# S6E1A1 register map
File version: 1.1
Registers are 8-bit, read-write, reset 0x0 unless marked. A register's access mark holds for its fields unless they carry their own. Offsets are from the block's base; [hi:lo] are bit positions; {n}, {i} and the like mark numbered series.

## ADC0 — ADC0 Registers
Base 0x40027000
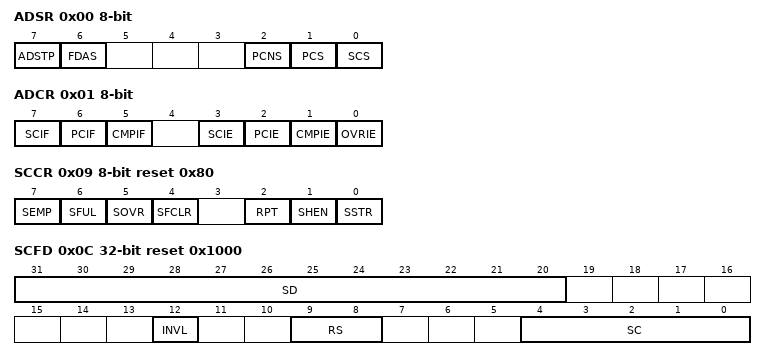
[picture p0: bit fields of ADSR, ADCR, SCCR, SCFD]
0x00 ADSR — A/D Status Register
  [7] ADSTP — A/D conversion forced stop bit
  [6] FDAS — FIFO data placement selection bit
  [2] PCNS ro — Priority conversion pending flag
  [1] PCS ro — Priority conversion status flag
  [0] SCS ro — Scan conversion status flag
0x01 ADCR — A/D Control Register
  [7] SCIF — Scan conversion interrupt request bit
  [6] PCIF — Priority conversion interrupt request bit
  [5] CMPIF — Conversion result comparison interrupt request bit
  [3] SCIE — Scan conversion interrupt enable bit
  [2] PCIE — Priority conversion interrupt enable bit
  [1] CMPIE — Conversion result comparison interrupt enable bit
  [0] OVRIE — FIFO overrun interrupt enable bit
0x08 SFNS — Scan Conversion FIFO Stage Count Setup Register
  [3:0] SFS — Scan conversion FIFO stage count setting bits
0x09 SCCR reset 0x80 — Scan Conversion Control Register
  [7] SEMP ro — Scan conversion FIFO empty bit
  [6] SFUL ro — Scan conversion FIFO full bit
  [5] SOVR — Scan conversion overrun flag
  [4] SFCLR — Scan conversion FIFO clear bit
  [2] RPT — Scan conversion repeat bit
  [1] SHEN — Scan conversion timer start enable bit
  [0] SSTR — Scan conversion start bit
0x0C SCFD 32-bit ro reset 0x1000 — Scan Conversion FIFO Data Register
  [31:20] SD — Scan conversion result
  [12] INVL — A/D conversion result disable bit
  [9:8] RS — Scan conversion start factor
  [4:0] SC — Conversion input channel bits
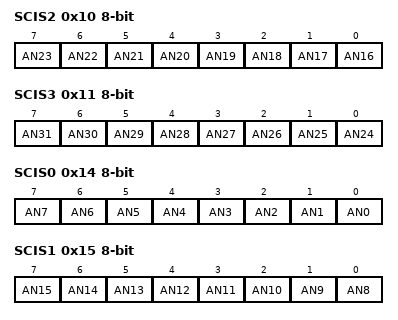
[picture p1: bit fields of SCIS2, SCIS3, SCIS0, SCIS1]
0x10 SCIS2 — Scan Conversion Input Selection Register 2
  [n-16] AN{n} (n=16..23) — AN{n} analog input selection bit
0x11 SCIS3 — Scan Conversion Input Selection Register 3
  [n-24] AN{n} (n=24..31) — AN{n} analog input selection bit
0x14 SCIS0 — Scan Conversion Input Selection Register 0
  [n] AN{n} (n=0..7) — AN{n} analog input selection bit
0x15 SCIS1 — Scan Conversion Input Selection Register 1
  [n-8] AN{n} (n=8..15) — AN{n} analog input selection bit
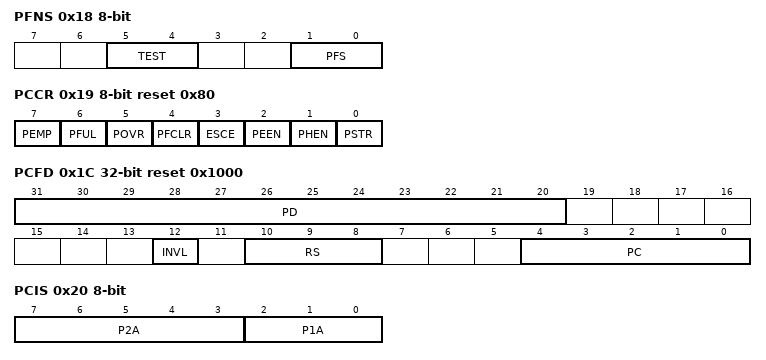
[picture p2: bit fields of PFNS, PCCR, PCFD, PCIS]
0x18 PFNS — Priority Conversion FIFO Stage Count Setup Register
  [5:4] TEST ro — Test bits
  [1:0] PFS — Priority conversion FIFO stage count setting bits
0x19 PCCR reset 0x80 — Priority Conversion Control Register
  [7] PEMP ro — Priority conversion FIFO empty bit
  [6] PFUL ro — Priority conversion FIFO full bit
  [5] POVR — Priority conversion overrun flag
  [4] PFCLR — Priority conversion FIFO clear bit
  [3] ESCE — External trigger analog input selection bit
  [2] PEEN — Priority conversion external start enable bit
  [1] PHEN — Priority conversion timer start enable bit
  [0] PSTR — Priority conversion start bit
0x1C PCFD 32-bit ro reset 0x1000 — Priority Conversion FIFO Data Register
  [31:20] PD — Priority conversion result
  [12] INVL — A/D conversion result disable bit
  [10:8] RS — Scan conversion start factor
  [4:0] PC — Conversion input channel bits
0x20 PCIS — Priority Conversion Input Selection Register
  [7:3] P2A — Priority level 2 analog input selection
  [2:0] P1A — Priority level 1 analog input selection
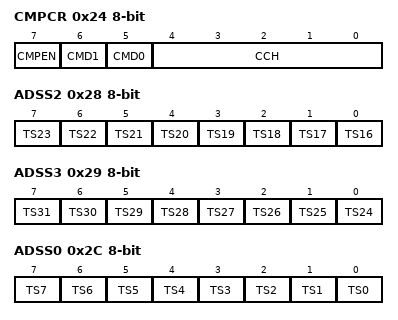
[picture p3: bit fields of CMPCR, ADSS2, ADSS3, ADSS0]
0x24 CMPCR — A/D Comparison Control Register
  [7] CMPEN — Conversion result comparison function operation enable bit
  [6] CMD1 — Comparison mode 1
  [5] CMD0 — Comparison mode 0
  [4:0] CCH — Comparison target analog input channel
0x26 CMPD 16-bit — A/D Comparison Value Setup Register
  [15:6] CMAD — A/D conversion compare value setting bits
0x28 ADSS2 — Sampling Time Selection Register 2
  [n-16] TS{n} (n=16..23) — AN{n} sampling time selection bit
0x29 ADSS3 — Sampling Time Selection Register 3
  [n-24] TS{n} (n=24..31) — AN{n} sampling time selection bit
0x2C ADSS0 — Sampling Time Selection Register 0
  [n] TS{n} (n=0..7) — AN{n} sampling time selection bit
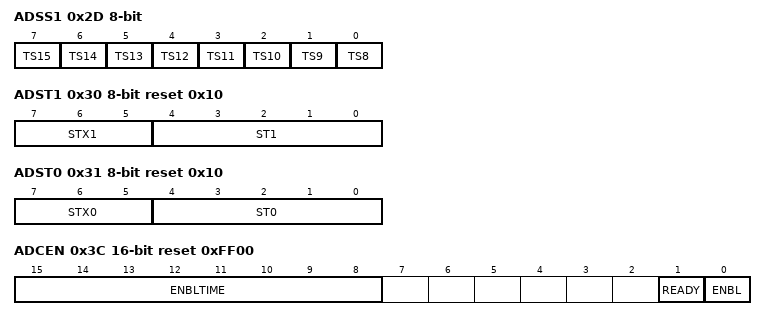
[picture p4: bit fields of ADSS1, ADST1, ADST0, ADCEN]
0x2D ADSS1 — Sampling Time Selection Register 1
  [n-8] TS{n} (n=8..15) — AN{n} sampling time selection bit
0x30 ADST1 reset 0x10 — Sampling Time Setup Register 1
  [7:5] STX1 — Sampling time N times setting bits
  [4:0] ST1 — Sampling time setting bits
0x31 ADST0 reset 0x10 — Sampling Time Setup Register 0
  [7:5] STX0 — Sampling time N times setting bits
  [4:0] ST0 — Sampling time setting bits
0x34 ADCT reset 0x7 — Frequency Division Ratio Setup Register
  [7:0] CT — Frequency division ratio setting bits
0x38 PRTSL — Priority Conversion Timer Trigger Selection Register
  [3:0] PRTSL — Priority conversion timer trigger selection bits
0x39 SCTSL — Scan Conversion Timer Trigger Selection Register
  [3:0] SCTSL — Scan conversion timer trigger selection bits
0x3C ADCEN 16-bit reset 0xFF00 — A/D Operation Enable Setup Register
  [15:8] ENBLTIME — Operation enable state transition cycle selection bits
  [1] READY ro — A/D operation enable state bit
  [0] ENBL — A/D operation enable bit
0x44 WCMRCIF 32-bit — Range Comparison Flag Register
  [0] RCINT — Range comparison interrupt factor flag bit
0x48 WCMRCOT 32-bit — Range Comparison Threshold Excess Flag Register
  [0] RCOOF — Threshold excess flag bit
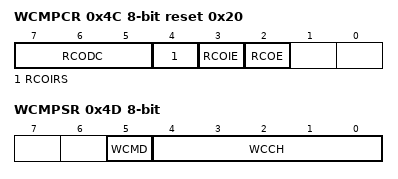
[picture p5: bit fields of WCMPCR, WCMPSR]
0x4C WCMPCR reset 0x20 — ERROR!!!!!!!!!!!!!!!!!!!!
  [7:5] RCODC — ERROR!!!!!!!!!!!!!!!!!!!!
  [4] RCOIRS — ERROR!!!!!!!!!!!!!!!!!!!!
  [3] RCOIE — ERROR!!!!!!!!!!!!!!!!!!!!
  [2] RCOE — ERROR!!!!!!!!!!!!!!!!!!!!
0x4D WCMPSR — ERROR!!!!!!!!!!!!!!!!!!!!
  [5] WCMD — ERROR!!!!!!!!!!!!!!!!!!!!
  [4:0] WCCH — ERROR!!!!!!!!!!!!!!!!!!!!
0x50 WCMPDL 16-bit — ERROR!!!!!!!!!!!!!!!!!!!!
  [15:6] CMLD
0x52 WCMPDH 16-bit — ERROR!!!!!!!!!!!!!!!!!!!!
  [15:6] CMHD
